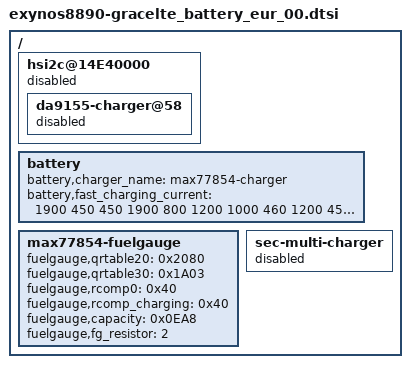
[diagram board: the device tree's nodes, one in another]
/*
 * SAMSUNG UNIVERSAL5433 board device tree source
 *
 * Copyright (c) 2013 Samsung Electronics Co., Ltd.
 *		http://www.samsung.com
 *
 * This program is free software; you can redistribute it and/or modify
 * it under the terms of the GNU General Public License version 2 as
 * published by the Free Software Foundation.
*/

#include "exynos8890-gracelte_common_battery.dtsi"
/ {
	hsi2c@14E40000 { /* hsi2c13 */
		status = "disabled";
		da9155-charger@58 {
			status = "disabled";
		};
	};

	battery {
		battery,charger_name = "max77854-charger";
		battery,fast_charging_current = <1900 450 450 1900 800 1200 1000 460 1200 450 1900 1900 1900 1600 1900 450 450 400 700 1300 300 1000 1500 450 1900 1900 1000 1900 80 1800 1000 1400 450 1000 1900 1900 1900 1900 1900>;
	};

	max77854-fuelgauge {
		fuelgauge,qrtable20 = <0x2080>;
		fuelgauge,qrtable30 = <0x1A03>;
		fuelgauge,rcomp0 = <0x40>;
		fuelgauge,rcomp_charging = <0x40>;
		fuelgauge,capacity = <0x0EA8>;
		fuelgauge,fg_resistor = <2>;
	};

	sec-multi-charger {
		status = "disabled";
	};
};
